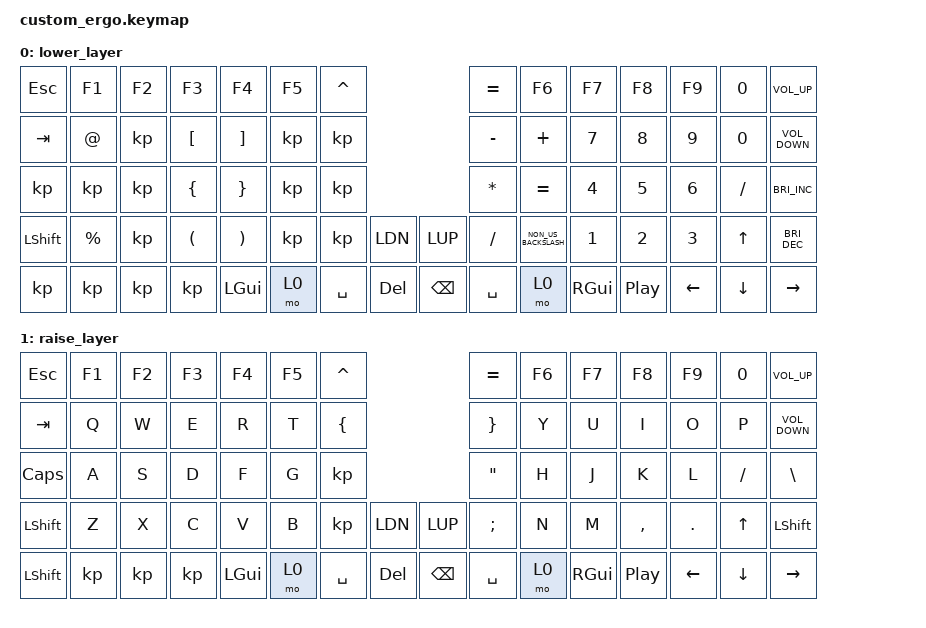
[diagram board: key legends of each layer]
/*
 * Copyright (c) 2020 The ZMK Contributors
 *
 * SPDX-License-Identifier: MIT
 */

#include <behaviors.dtsi>
#include <dt-bindings/zmk/keys.h>

/ {
    keymap {
        compatible = "zmk,keymap";

        default_layer {
            // ----------------------------------------------------------------------------------------------------------
            // | ESC  |  1  |  2  |  3  |  4  |  5  |  -  |                 |  =  |  Y  |  U   |  I  |  O  |  P  | VLUP |
            // | TAB  |  Q  |  W  |  E  |  R  |  T  |  {  |                 |  }  |  Y  |  U   |  I  |  O  |  P  | VODN |
            // | TAB  |  A  |  S  |  D  |  F  |  G  |  *  |                 |  "  |  H  |  J   |  K  |  L  |  /  |  \   |
            // | SHFT |  Z  |  X  |  C  |  V  |  B  |  *  |  *  |    |  *   |  ;  |  N  |  M   |  ,  |  .  |  UP | SHFT |
            // |   *  |  *  |  *  |  *  | COM |  1  | SPC | DEL |    | BSPC | SPC |  2  | COM  | PLY | LFT | DWN | RGT  |

            bindings = <
&kp ESC       &kp N1    &kp N2          &kp N3  &kp N4     &kp N5                        
&kp TAB       &kp Q     &kp R           &kp T   &kp Y      &kp TAB                         
&kp G         &kp BSLH  &kp LEFT_SHIFT  &kp Z   &kp C      &kp V                           
&kp LEFT_GUI  &mo 1     &kp SPACE       &kp     &kp SPACE  &kp SPACE  &kp SPACE  
        };

        lower_layer {
            // ----------------------------------------------------------------------------------------------------------
            // | ESC  |  1  |  2  |  3  |  4  |  5  |  -  |                 |  =  |  Y  |  U   |  I  |  O  | BRUP | VLUP |
            // | TAB  |  Q  |  W  |  E  |  R  |  T  |  {  |                 |  }  |  Y  |  U   |  I  |  O  | BRDN | VODN |
            // | CTRL |  A  |  S  |  D  |  F  |  G  |  *  |                 |  "  |  H  |  J   |  K  |  L  |  /   |  \   |
            // | SHFT |  Z  |  X  |  C  |  V  |  B  |  *  |  *  |    |  *   |  ;  |  N  |  M   |  ,  |  .  |  UP  | SHFT |
            // |   *  |  *  |  *  |  *  | COM |  0  | SPC | DEL |    | BSPC | SPC |  0  | COM  | PLY | LFT |  DWN | RGT  |

            bindings = <
&kp ESC         &kp F1       &kp F2  &kp F3                &kp F4                 &kp F5  &kp CARET                     &kp EQUAL     &kp F6                &kp F7         &kp F8            &kp F9          &kp N0          &kp C_VOLUME_UP
&kp TAB         &kp AT_SIGN  &kp     &kp LEFT_BRACKET      &kp RIGHT_BRACKET      &kp     &kp                           &kp MINUS     &kp PLUS              &kp N7         &kp N8            &kp N9          &kp N0          &kp C_VOLUME_DOWN
&kp             &kp          &kp     &kp LEFT_BRACE        &kp RIGHT_BRACE        &kp     &kp                           &kp ASTERISK  &kp EQUAL             &kp NUMBER_4   &kp N5            &kp NUMBER_6    &kp FSLH        &kp C_BRIGHTNESS_INC
&kp LEFT_SHIFT  &kp PERCENT  &kp     &kp LEFT_PARENTHESIS  &kp RIGHT_PARENTHESIS  &kp     &kp        &kp LDN  &kp LUP   &kp SLASH     &kp NON_US_BACKSLASH  &kp NUMBER_1   &kp NUMBER_2      &kp NUMBER_3    &kp UP_ARROW    &kp C_BRIGHTNESS_DEC
&kp             &kp          &kp     &kp                   &kp LEFT_GUI           &mo 0   &kp SPACE  &kp DEL  &kp BSPC  &kp SPACE     &mo 0                 &kp RIGHT_GUI  &kp C_PLAY_PAUSE  &kp LEFT_ARROW  &kp DOWN_ARROW  &kp RIGHT_ARROW
            >;
        };

        raise_layer {
            // ----------------------------------------------------------------------------------------------------------
            // | ESC  |  1  |  2  |  3  |  4  |  5  |  -  |                 |  =  |  Y  |  U   |  I  |  O  |  P  | VLUP |
            // | TAB  |  Q  |  W  |  E  |  R  |  T  |  {  |                 |  }  |  Y  |  U   |  I  |  O  |  P  | VODN |
            // | CTRL |  A  |  S  |  D  |  F  |  G  |  *  |                 |  "  |  H  |  J   |  K  |  L  |  /  |  \   |
            // | SHFT |  Z  |  X  |  C  |  V  |  B  |  *  |  *  |    |  *  |  ;  |  N  |  M   |  ,  |  .  |  UP | SHFT |
            // |   *  |  *  |  *  |  *  | COM |  0  | SPC | DEL |    | BSPC | SPC |  0  | COM  | PLY | LFT | DWN | RGT  |

            bindings = <
&kp ESC         &kp F1  &kp F2  &kp F3  &kp F4        &kp F5  &kp CARET                     &kp EQUAL      &kp F6  &kp F7         &kp F8            &kp F9          &kp N0          &kp C_VOLUME_UP
&kp TAB         &kp Q   &kp W   &kp E   &kp R         &kp T   &kp LBRC                      &kp RBRC       &kp Y   &kp U          &kp I             &kp O           &kp P           &kp C_VOLUME_DOWN
&kp CAPS        &kp A   &kp S   &kp D   &kp F         &kp G   &kp                           &kp DQT        &kp H   &kp J          &kp K             &kp L           &kp FSLH        &kp BSLH
&kp LEFT_SHIFT  &kp Z   &kp X   &kp C   &kp V         &kp B   &kp        &kp LDN  &kp LUP   &kp SEMICOLON  &kp N   &kp M          &kp COMMA         &kp DOT         &kp UP_ARROW    &kp LSHFT
&kp LSHFT       &kp     &kp     &kp     &kp LEFT_GUI  &mo 0   &kp SPACE  &kp DEL  &kp BSPC  &kp SPACE      &mo 0   &kp RIGHT_GUI  &kp C_PLAY_PAUSE  &kp LEFT_ARROW  &kp DOWN_ARROW  &kp RIGHT_ARROW
            >;
        };
    };
};
